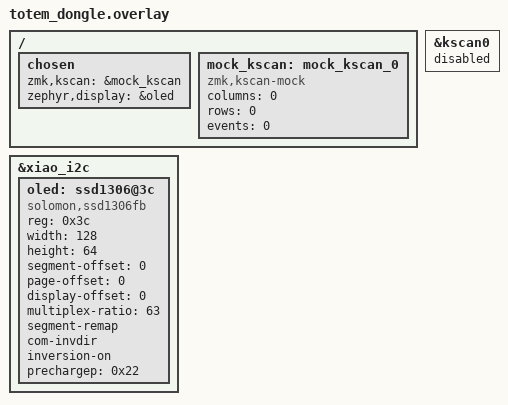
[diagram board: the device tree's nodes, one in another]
#include "totem.dtsi"

/ {
    chosen {
        /delete-property/ zmk,kscan;        // Remove the kscan reference from totem.dtsi
        zmk,kscan = &mock_kscan;            // Add our mock kscan instead
        zephyr,display = &oled;
    };
    
    // Create a mock kscan with no keys
    mock_kscan: mock_kscan_0 {
        compatible = "zmk,kscan-mock";
        columns = <0>;
        rows = <0>;
        events = <0>;
    };
};

// Disable the real kscan inherited from totem.dtsi
&kscan0 {
    status = "disabled";
};

&xiao_i2c {
    status = "okay";
    
    oled: ssd1306@3c {
        compatible = "solomon,ssd1306fb";
        reg = <0x3c>;
        width = <128>;
        height = <64>;
        segment-offset = <0>;
        page-offset = <0>;
        display-offset = <0>;
        multiplex-ratio = <63>;
        segment-remap;
        com-invdir;
        inversion-on;
        prechargep = <0x22>;
    };
};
